# USCI_B0__SPI_Mode_4 register map
Vendor: Texas Instruments
Peripheral module from a debugger description file (folder msp430).
Registers are 16-bit, access not given, no defined reset value unless marked. A register's access mark holds for its fields unless they carry their own. Offsets are as the file gives them; lines under a group give offsets from that group; [hi:lo] are bit positions; {n}, {i} and the like mark numbered series; 'fields as' and 'values as' point back to an identical list; <NAME> marks a mode.

## USCI_B0_SPI_Mode
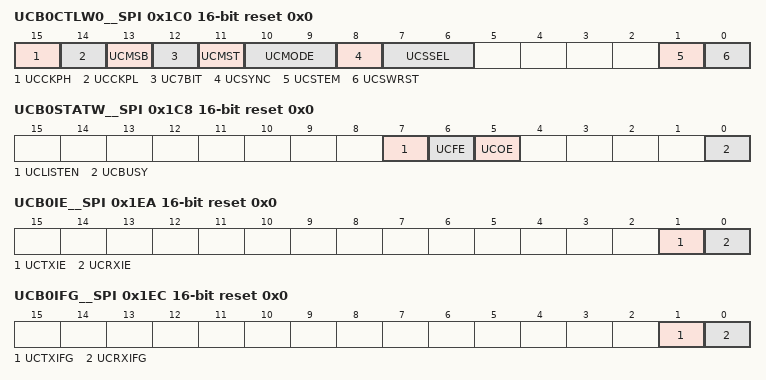
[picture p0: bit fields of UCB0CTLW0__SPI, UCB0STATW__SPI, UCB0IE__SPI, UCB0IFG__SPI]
0x1C0 UCB0CTLW0__SPI rw reset 0x0 — USCI B0 Control Word Register 0
  [15] UCCKPH — Sync. Mode: Clock Phase
  [14] UCCKPL — Sync. Mode: Clock Polarity
  [13] UCMSB — Sync. Mode: MSB first 0:LSB / 1:MSB
  [12] UC7BIT — Sync. Mode: Data Bits 0:8-bits / 1:7-bits
  [11] UCMST — Sync. Mode: Master Select
  [10:9] UCMODE — Sync. Mode: USCI Mode 1
    {v}=Sync. Mode: USCI Mode: {v} (v=0..3)
  [8] UCSYNC — Sync-Mode 0:UART-Mode / 1:SPI-Mode
  [7:6] UCSSEL — USCI 1 Clock Source Select 1
    {v}=USCI 0 Clock Source: {v} (v=0..3)
  [1] UCSTEM — USCI STE Mode
  [0] UCSWRST — USCI Software Reset
0x1C0 UCB0CTL1__SPI 8-bit — USCI B0 Control Register 1
0x1C1 UCB0CTL0__SPI 8-bit — USCI B0 Control Register 0
0x1C6 UCB0BRW__SPI — USCI B0 Baud Word Rate 0
0x1C6 UCB0BR0__SPI 8-bit — USCI B0 Baud Rate 0
0x1C7 UCB0BR1__SPI 8-bit — USCI B0 Baud Rate 1
0x1C8 UCB0STATW__SPI rw reset 0x0 — USCI B0 Status Register
  [7] UCLISTEN — USCI Listen mode
  [6] UCFE — USCI Frame Error Flag
  [5] UCOE — USCI Overrun Error Flag
  [0] UCBUSY — USCI Busy Flag
0x1CC UCB0RXBUF__SPI — USCI B0 Receive Buffer
0x1CE UCB0TXBUF__SPI — USCI B0 Transmit Buffer
0x1EA UCB0IE__SPI rw reset 0x0 — USCI B0 Interrupt Enable Register
  [1] UCTXIE — USCI Transmit Interrupt Enable
  [0] UCRXIE — USCI Receive Interrupt Enable
0x1EC UCB0IFG__SPI rw reset 0x0 — USCI B0 Interrupt Flags Register
  [1] UCTXIFG — SPI Transmit Interrupt Flag
  [0] UCRXIFG — SPI Receive Interrupt Flag
0x1EE UCB0IV__SPI — USCI B0 Interrupt Vector Register
